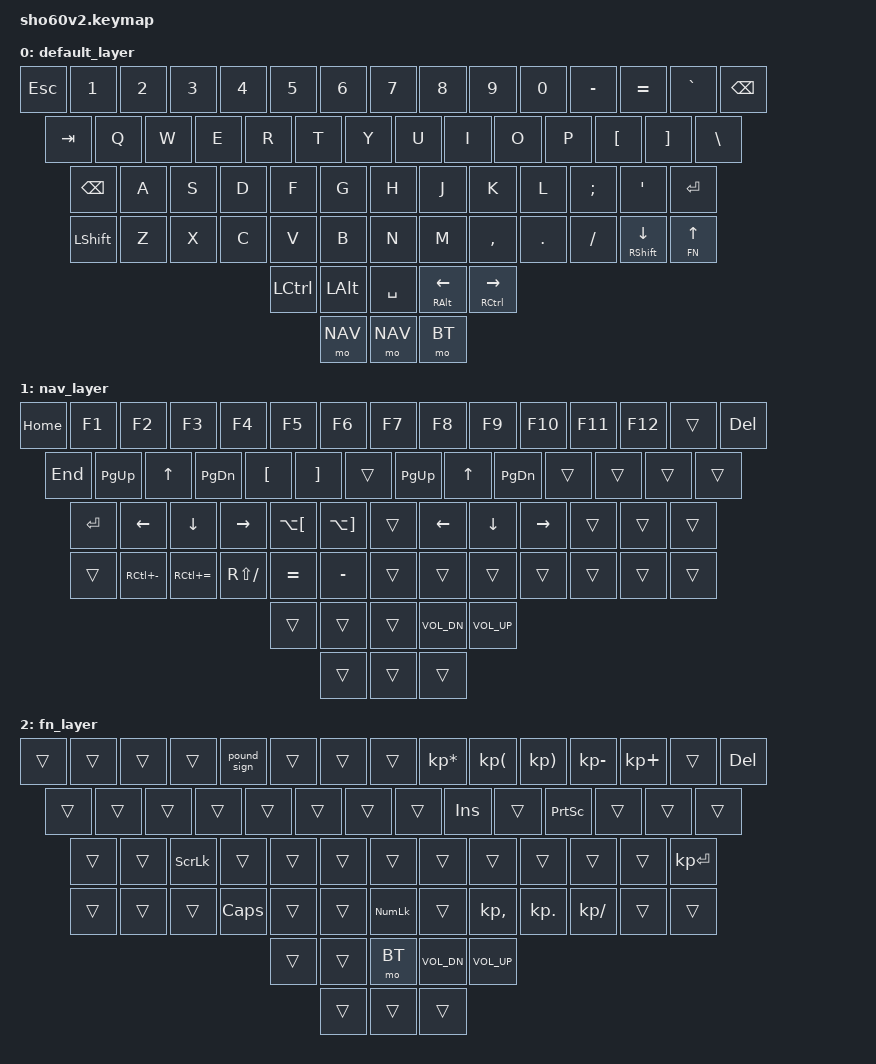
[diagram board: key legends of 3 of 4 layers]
#include <behaviors.dtsi>
#include <dt-bindings/zmk/keys.h>
#include <dt-bindings/zmk/bt.h>
#include <dt-bindings/zmk/outputs.h>

&lt {
    tapping-term-ms = <180>;
};

#define DEFAULT 0
#define NAV 1
#define FN 2
#define BT 3

/ {
    macros {
        pound_sign: pound_sign {
            compatible = "zmk,behavior-macro";
            #binding-cells = <0>;
            bindings
                = <&macro_press &kp LALT>
                , <&macro_tap &kp KP_N0 &kp KP_N1 &kp KP_N6 &kp KP_N3>
                , <&macro_release &kp LALT>
                ;
        };
    };

    keymap {
        compatible = "zmk,keymap";

        default_layer {
            bindings = <
                &kp ESC &kp N1 &kp N2 &kp N3 &kp N4 &kp N5 &kp N6 &kp N7 &kp N8 &kp N9 &kp N0 &kp MINUS &kp EQUAL &kp GRAVE &kp BSPC
                &kp TAB &kp Q &kp W &kp E &kp R &kp T &kp Y &kp U &kp I &kp O &kp P &kp LBKT &kp RBKT &kp BSLH
                &kp BSPC &kp A &kp S &kp D &kp F &kp G &kp H &kp J &kp K &kp L &kp SEMI &kp SQT &kp ENTER
                &kp LSHFT &kp Z &kp X &kp C &kp V &kp B &kp N &kp M &kp COMMA &kp DOT &kp SLASH &mt RSHFT DOWN &lt FN UP
                        &kp LCTRL &kp LALT                 &kp SPACE                  &mt RALT LEFT &mt RCTRL RIGHT
                &mo NAV  &mo NAV  &mo BT
            >;
        };

        nav_layer {
            bindings = <
                &kp HOME &kp F1 &kp F2 &kp F3 &kp F4 &kp F5 &kp F6 &kp F7 &kp F8 &kp F9 &kp F10 &kp F11 &kp F12 &trans &kp DEL
                &kp END   &kp PG_UP &kp UP &kp PG_DN &kp LBKT &kp RBKT &trans &kp PG_UP &kp UP &kp PG_DN &trans &trans &trans &trans
                &kp ENTER   &kp LEFT &kp DOWN &kp RIGHT &kp LA(LBKT) &kp LA(RBKT) &trans &kp LEFT &kp DOWN &kp RIGHT &trans &trans &trans
                &trans        &kp RC(MINUS) &kp RC(EQUAL) &kp RS(SLASH) &kp EQUAL &kp MINUS &trans &trans &trans &trans &trans &trans        &trans
                        &trans &trans               &trans                    &kp C_VOL_DN &kp C_VOL_UP
                &trans  &trans  &trans
            >;
        };

        fn_layer {
            bindings = <
                &trans &trans &trans &trans &pound_sign &trans &trans &trans &kp KP_ASTERISK &kp KP_LPAR &kp KP_RPAR &kp KP_MINUS &kp KP_PLUS &trans &kp DEL
                &trans &trans &trans &trans &trans &trans &trans &trans &kp INS &trans &kp PSCRN &trans &trans &trans
                &trans &trans &kp SLCK &trans &trans &trans &trans &trans &trans &trans &trans &trans &kp KP_ENTER
                &trans  &trans &trans &kp CAPS &trans &trans &kp KP_NLCK &trans &kp KP_COMMA &kp KP_DOT &kp KP_SLASH &trans &trans
                        &trans &trans               &mo BT                    &kp C_VOL_DN &kp C_VOL_UP
                &trans &trans &trans
            >;
        };

        bt_layer {
            bindings = <
                &bt BT_CLR_ALL &bt BT_SEL 0 &bt BT_SEL 1 &bt BT_SEL 2 &none &none &none &none &none &none &none &none &none &none &none
                &out OUT_TOG &none &none &none &none &none &none &none &none &none &none &none &none &none
                &none &none &none &none &none &none &none &none &none &none &none &none &none
                &none  &none &none &none &none &none &none &none &none &none &none &none &none
                        &none &none               &none                    &none &none &none
                &none &none &none
            >;
        };
    };
};
